# BAT32G157 register map
Vendor: Cmsemicon; Series: BAT32G157; File version: 1.0
CPU: CM0+ r0p1, little endian, no MPU, no FPU, VTOR, 2 interrupt priority bits
Registers are 8-bit, read-write, reset 0x0 unless marked. A register's access mark holds for its fields unless they carry their own. Offsets are from the block's base; [hi:lo] are bit positions; {n}, {i} and the like mark numbered series; 'fields as' and 'values as' point back to an identical list.

## RST — Reset Function
Base 0x40020420
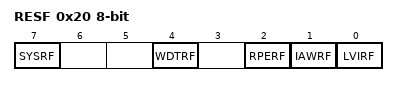
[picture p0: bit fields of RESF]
0x20 RESF ro — Reset flag register
  [all] fields
    0=NONE (Internal reset request is not generated, or the RESF register is cleared.); 1=DONE (Internal reset request is generated.)
  [7] SYSRF read-clears — Internal reset request by system reset request(AIRCR.SYSRESETREQ)
  [4] WDTRF read-clears — Internal reset request by watchdog timer(WDT)
  [2] RPERF read-clears — Internal reset request by RAM parity
  [1] IAWRF read-clears — Internal reset request by illegal-memory access
  [0] LVIRF read-clears — Internal reset request by voltage detector

## LVD — Voltage detector
Base 0x40020440
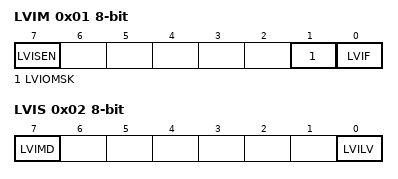
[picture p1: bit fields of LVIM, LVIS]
0x01 LVIM — Voltage detection register
  [7] LVISEN ro — Enable rewritting LVIS register
    0=Disable (Disabling of rewriting the LVIS register); 1=Enable (Enabling of rewriting the LVIS register)
  [1] LVIOMSK ro — Mask status flag of LVD output
    0=Invalid (Mask of LVD output is invalid); 1=Valid (Mask of LVD output is valid)
  [0] LVIF ro — Voltage detection flag
    0=GE (Supply voltage (VDD) greater or equal to detection voltage (VLVD), or when LVD is off); 1=LT (Supply voltage (VDD) less than detection voltage (VLVD))
0x02 LVIS — Voltage detection level register
  [7] LVIMD — Operation mode of voltage detection
    0=IRQ (interrupt mode); 1=reset mode
  [0] LVILV — LVD detection level
    0=High-voltage detection level (VLVDH); 1=Low (Low-voltage detection level (VLVDL or VLVD))

## DIV — Hardware divider
Base 0x4001C000
0x00 DIVIDEND 32-bit
0x04 DIVISOR 32-bit
0x08 QUOTIENT 32-bit ro
0x0C REMAINDER 32-bit ro
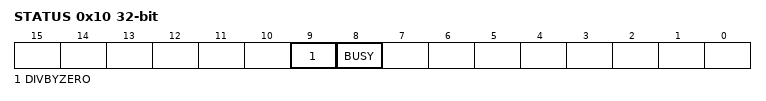
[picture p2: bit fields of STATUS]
0x10 STATUS 32-bit ro
  [9] DIVBYZERO — divider zero flag
  [8] BUSY — divider busy flag

## TM81 — General Purpose Timer 4
Base 0x40042180
{0x0+2i} TCR1{i} (i=0..7) 16-bit ro reset 0xFFFF — Timer count register 0{i}
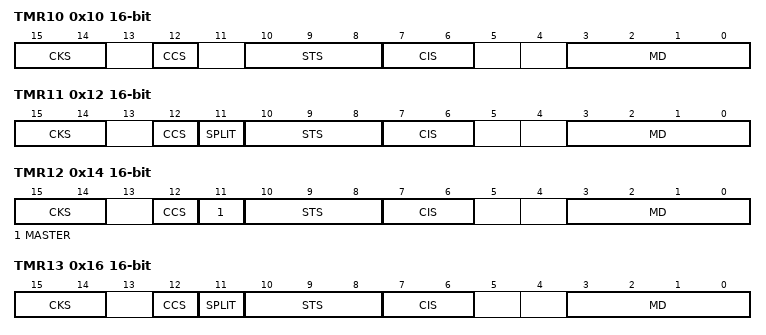
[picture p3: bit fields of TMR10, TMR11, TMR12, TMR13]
0x10 TMR10 16-bit — Timer mode register mn
  [15:14] CKS — Selection of operation clock (fMCK) of channel n
  [12] CCS — Selection of count clock (fTCLK) of channel n
  [10:8] STS — Setting of start trigger or capture trigger of channel n
  [7:6] CIS — Selection of TImn pin input valid edge
  [3:0] MD — Operation mode of channel n
0x12 TMR11 16-bit — Timer mode register mn
  [15:14] CKS — Selection of operation clock (fMCK) of channel n
  [12] CCS — Selection of count clock (fTCLK) of channel n
  [11] SPLIT — Selection of 8 or 16-bit timer operation for channels 1 and 3
  [10:8] STS — Setting of start trigger or capture trigger of channel n
  [7:6] CIS — Selection of TImn pin input valid edge
  [3:0] MD — Operation mode of channel n
0x14 TMR12 16-bit — Timer mode register mn
  [15:14] CKS — Selection of operation clock (fMCK) of channel n
  [12] CCS — Selection of count clock (fTCLK) of channel n
  [11] MASTER — Selection between using channel n independently or simultaneously with another channel (as a slave or master)
  [10:8] STS — Setting of start trigger or capture trigger of channel n
  [7:6] CIS — Selection of TImn pin input valid edge
  [3:0] MD — Operation mode of channel n
0x16 TMR13 16-bit — Timer mode register mn
  fields as TMR11
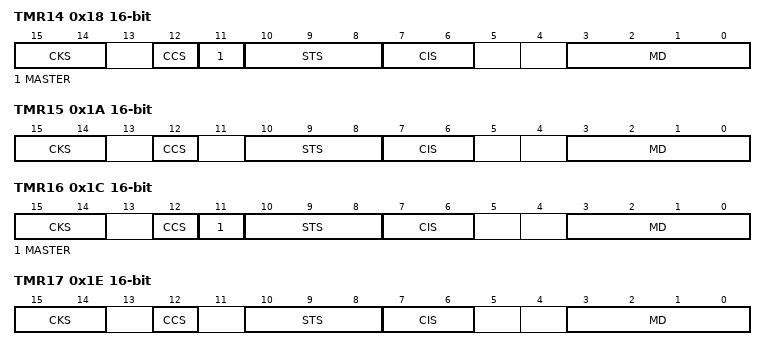
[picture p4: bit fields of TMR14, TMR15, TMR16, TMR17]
0x18 TMR14 16-bit — Timer mode register mn
  fields as TMR12
0x1A TMR15 16-bit — Timer mode register mn
  fields as TMR10
0x1C TMR16 16-bit — Timer mode register mn
  fields as TMR12
0x1E TMR17 16-bit — Timer mode register mn
  fields as TMR10
{0xC+2i} TSR{i} 16-bit ro (i=10..17) — Timer status register mn
  [0] OVF — Counter overflow status of channel n
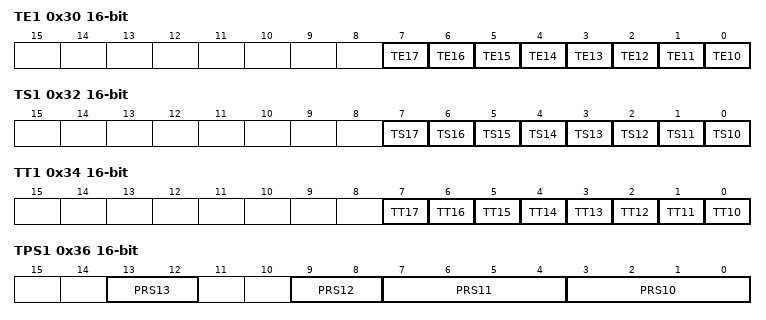
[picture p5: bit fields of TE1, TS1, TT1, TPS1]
0x30 TE1 16-bit ro — Timer channel enable status register m
  [n-10] TE{n} (n=10..17) — Indication of operation enable/stop status of channel {n-10}
0x32 TS1 16-bit — Timer channel start register 0
  [n-10] TS{n} (n=10..17) — Operation enable (start) trigger of channel {n-10}
0x34 TT1 16-bit — Timer channel stop register 0
  [n-10] TT{n} (n=10..17) — Operation stop trigger of channel {n-10}
0x36 TPS1 16-bit — Timer clock select register 0
  [13:12] PRS13 — Prescaler 3
  [9:8] PRS12 — Prescaler 2
  [7:4] PRS11 — Prescaler 1
  [3:0] PRS10 — Prescaler 0
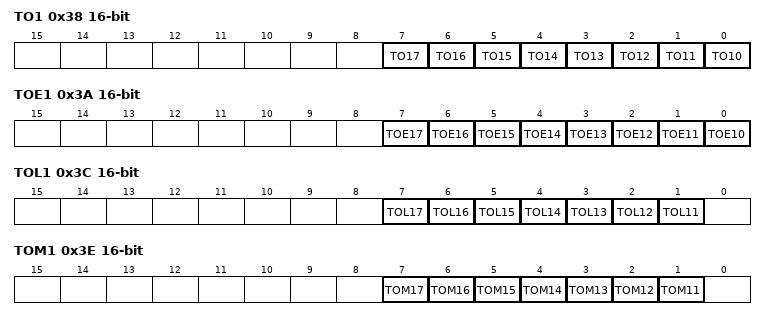
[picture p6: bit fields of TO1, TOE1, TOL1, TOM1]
0x38 TO1 16-bit — Timer output register 0
  [n-10] TO{n} (n=10..17) — Timer output of channel {n-10}
0x3A TOE1 16-bit — Timer output enable register 0
  [n-10] TOE{n} (n=10..17) — Timer output enable of channel {n-10}
0x3C TOL1 16-bit — Timer output level register 0
  [n-10] TOL{n} (n=11..17) — Control of timer output level of channel {n-10}
0x3E TOM1 16-bit — Timer output mode register 0
  [n-10] TOM{n} (n=11..17) — Control of timer output mode of channel {n-10}
0x198 TDR10 16-bit — Timer data register 00
0x19A TDR11 16-bit — Timer data register 01
0x19A TDR11L (alternate view of TDR11) — Timer data lower register 11
0x19B TDR11H (alternate view of TDR11) — Timer data higher register 11
{0x1CC+2i} TDR{i} 16-bit (i=12..17) — Timer data register {i-10:02}
0x1E6 TDR13L (alternate view of TDR13) — Timer data lower register 13
0x1E7 TDR13H (alternate view of TDR13) — Timer data higher register 13

## Notices in the file
Copyright (C) 2012-2014 ARM Limited. All rights reserved.
Purpose: System Viewer Description (SVD) Example (Schema Version 1.1)
This is a description of a none-existent and incomplete device
for demonstration purposes only.
Redistribution and use in source and binary forms, with or without
modification, are permitted provided that the following conditions are met:
- Redistributions of source code must retain the above copyright
notice, this list of conditions and the following disclaimer.
- Redistributions in binary form must reproduce the above copyright
notice, this list of conditions and the following disclaimer in the
documentation and/or other materials provided with the distribution.
- Neither the name of ARM nor the names of its contributors may be used
to endorse or promote products derived from this software without
specific prior written permission.
THIS SOFTWARE IS PROVIDED BY THE COPYRIGHT HOLDERS AND CONTRIBUTORS "AS IS"
AND ANY EXPRESS OR IMPLIED WARRANTIES, INCLUDING, BUT NOT LIMITED TO, THE
IMPLIED WARRANTIES OF MERCHANTABILITY AND FITNESS FOR A PARTICULAR PURPOSE
ARE DISCLAIMED. IN NO EVENT SHALL COPYRIGHT HOLDERS AND CONTRIBUTORS BE
LIABLE FOR ANY DIRECT, INDIRECT, INCIDENTAL, SPECIAL, EXEMPLARY, OR
CONSEQUENTIAL DAMAGES (INCLUDING, BUT NOT LIMITED TO, PROCUREMENT OF
SUBSTITUTE GOODS OR SERVICES; LOSS OF USE, DATA, OR PROFITS; OR BUSINESS
INTERRUPTION) HOWEVER CAUSED AND ON ANY THEORY OF LIABILITY, WHETHER IN
CONTRACT, STRICT LIABILITY, OR TORT (INCLUDING NEGLIGENCE OR OTHERWISE)
ARISING IN ANY WAY OUT OF THE USE OF THIS SOFTWARE, EVEN IF ADVISED OF THE
POSSIBILITY OF SUCH DAMAGE.
